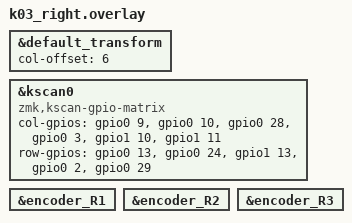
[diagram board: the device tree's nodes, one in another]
#include "k03.dtsi"

&default_transform {
    col-offset = <6>;
};

&kscan0 {
    compatible = "zmk,kscan-gpio-matrix";

    col-gpios
        = <&gpio0  9 GPIO_ACTIVE_HIGH>
        , <&gpio0 10 GPIO_ACTIVE_HIGH>
        , <&gpio0 28 GPIO_ACTIVE_HIGH>
        , <&gpio0  3 GPIO_ACTIVE_HIGH>
        , <&gpio1 10 GPIO_ACTIVE_HIGH>
        , <&gpio1 11 GPIO_ACTIVE_HIGH>
        ;

    row-gpios
        = <&gpio0 13 (GPIO_ACTIVE_HIGH | GPIO_PULL_DOWN)>
        , <&gpio0 24 (GPIO_ACTIVE_HIGH | GPIO_PULL_DOWN)>
        , <&gpio1 13 (GPIO_ACTIVE_HIGH | GPIO_PULL_DOWN)>
        , <&gpio0  2 (GPIO_ACTIVE_HIGH | GPIO_PULL_DOWN)>
        , <&gpio0 29 (GPIO_ACTIVE_HIGH | GPIO_PULL_DOWN)>
        ;
};

&encoder_R1 {
    status = "okay";
};

&encoder_R2 {
    status = "okay";
};

&encoder_R3 {
    status = "okay";
};
